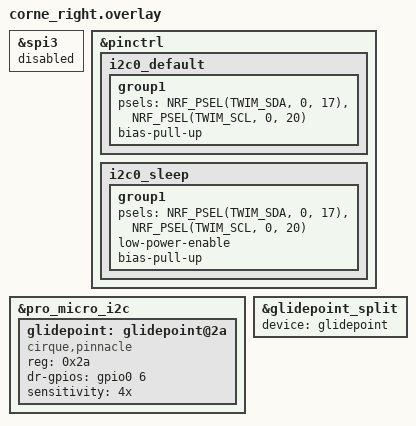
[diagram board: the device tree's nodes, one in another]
/* Right (peripheral) side overlay */
#include "corne_common.dtsi"

/* Disable RGB SPI3 to free P0.06 for Cirque DR pin */
&spi3 {
	status = "disabled";
};

/* Enable internal pull-ups on I2C pins (right side has no OLED with external pull-ups) */
&pinctrl {
	i2c0_default: i2c0_default {
		group1 {
			psels = <NRF_PSEL(TWIM_SDA, 0, 17)>,
				<NRF_PSEL(TWIM_SCL, 0, 20)>;
			bias-pull-up;
		};
	};

	i2c0_sleep: i2c0_sleep {
		group1 {
			psels = <NRF_PSEL(TWIM_SDA, 0, 17)>,
				<NRF_PSEL(TWIM_SCL, 0, 20)>;
			low-power-enable;
			bias-pull-up;
		};
	};
};

&pro_micro_i2c {
	glidepoint: glidepoint@2a {
		compatible = "cirque,pinnacle";
		reg = <0x2a>;
		status = "okay";
		dr-gpios = <&gpio0 6 GPIO_ACTIVE_HIGH>;
		sensitivity = "4x";
	};
};

&glidepoint_split {
	device = <&glidepoint>;
};
